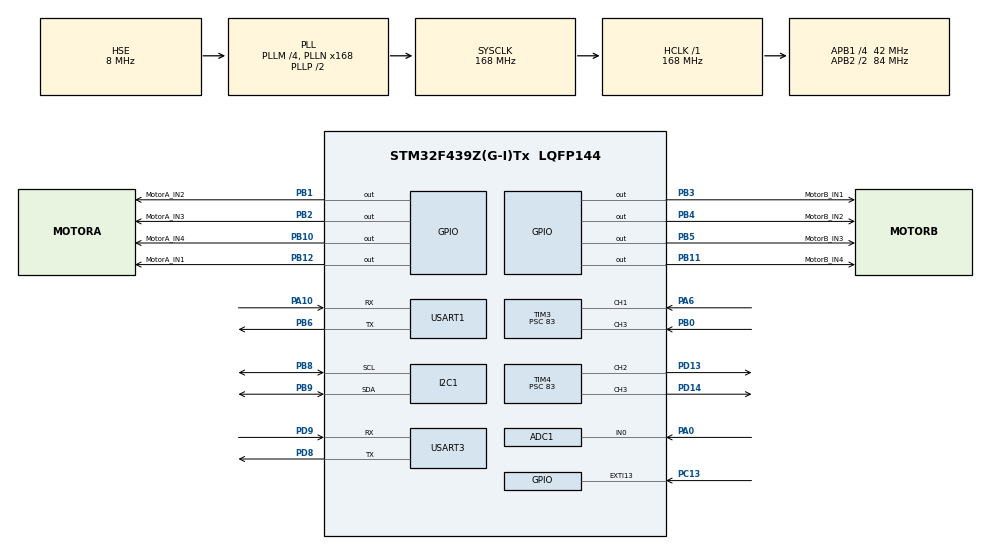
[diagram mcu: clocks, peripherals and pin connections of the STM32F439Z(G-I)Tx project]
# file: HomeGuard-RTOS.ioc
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ADC1.Channel-0\#ChannelRegularConversion=ADC_CHANNEL_0
ADC1.NbrOfConversionFlag=1
ADC1.Rank-0\#ChannelRegularConversion=1
ADC1.SamplingTime-0\#ChannelRegularConversion=ADC_SAMPLETIME_3CYCLES
ADC1.master=1
FREERTOS.Tasks01=defaultTask,24,128,StartDefaultTask,Default,NULL,Dynamic,NULL,NULL
FREERTOS.configENABLE_FPU=1
FREERTOS.configUSE_NEWLIB_REENTRANT=1
Mcu.Family=STM32F4
Mcu.Name=STM32F439Z(G-I)Tx
Mcu.Package=LQFP144
NVIC.EXTI15_10_IRQn=true\:5\:0\:false\:false\:true\:true\:true\:true\:true
NVIC.PriorityGroup=NVIC_PRIORITYGROUP_4
NVIC.TIM3_IRQn=true\:5\:0\:false\:false\:true\:true\:true\:true\:true
NVIC.TIM5_IRQn=true\:5\:0\:false\:false\:true\:true\:true\:true\:true
NVIC.TIM6_DAC_IRQn=true\:15\:0\:false\:false\:true\:false\:false\:true\:true
NVIC.TimeBase=TIM6_DAC_IRQn
NVIC.TimeBaseIP=TIM6
NVIC.USART1_IRQn=true\:5\:0\:false\:false\:true\:true\:true\:true\:true
PA0/WKUP.Signal=ADCx_IN0
PA10.Mode=Asynchronous
PA10.Signal=USART1_RX
PA6.Signal=S_TIM3_CH1
PB0.Signal=S_TIM3_CH3
PB1.GPIO_Label=MotorA_IN2
PB1.Signal=GPIO_Output
PB10.GPIO_Label=MotorA_IN4
PB10.Signal=GPIO_Output
PB11.GPIO_Label=MotorB_IN4
PB11.Signal=GPIO_Output
PB12.GPIO_Label=MotorA_IN1
PB12.Signal=GPIO_Output
PB2/BOOT1.GPIO_Label=MotorA_IN3
PB2/BOOT1.Signal=GPIO_Output
PB3.GPIO_Label=MotorB_IN1
PB3.Signal=GPIO_Output
PB4.GPIO_Label=MotorB_IN2
PB4.Signal=GPIO_Output
PB5.GPIO_Label=MotorB_IN3
PB5.Signal=GPIO_Output
PB6.Mode=Asynchronous
PB6.Signal=USART1_TX
PB8.Mode=I2C
PB8.Signal=I2C1_SCL
PB9.Mode=I2C
PB9.Signal=I2C1_SDA
PC13.GPIO_ModeDefaultEXTI=GPIO_MODE_IT_FALLING
PC13.Signal=GPXTI13
PC14/OSC32_IN.Mode=LSE-External-Oscillator
PC14/OSC32_IN.Signal=RCC_OSC32_IN
PC15/OSC32_OUT.Mode=LSE-External-Oscillator
PC15/OSC32_OUT.Signal=RCC_OSC32_OUT
PD13.Signal=S_TIM4_CH2
PD14.Signal=S_TIM4_CH3
PD8.Mode=Asynchronous
PD8.Signal=USART3_TX
PD9.Mode=Asynchronous
PD9.Signal=USART3_RX
PH0/OSC_IN.Mode=HSE-External-Oscillator
PH0/OSC_IN.Signal=RCC_OSC_IN
PH1/OSC_OUT.Mode=HSE-External-Oscillator
PH1/OSC_OUT.Signal=RCC_OSC_OUT
ProjectManager.HeapSize=0x200
ProjectManager.StackSize=0x400
ProjectManager.TargetToolchain=STM32CubeIDE
RCC.48MHZClocksFreq_Value=48000000
RCC.AHBFreq_Value=168000000
RCC.APB1CLKDivider=RCC_HCLK_DIV4
RCC.APB1Freq_Value=42000000
RCC.APB1TimFreq_Value=84000000
RCC.APB2CLKDivider=RCC_HCLK_DIV2
RCC.APB2Freq_Value=84000000
RCC.APB2TimCLKDivider=2
RCC.APB2TimFreq_Value=168000000
RCC.CortexFreq_Value=168000000
RCC.HCLKFreq_Value=168000000
RCC.HSE_VALUE=8000000
RCC.HSI_VALUE=16000000
RCC.PLLM=4
RCC.PLLMUL=RCC_PLL_MUL9
RCC.PLLN=168
RCC.PLLQ=7
RCC.PLLSourceVirtual=RCC_PLLSOURCE_HSE
RCC.PRESCALERUSB=RCC_USBCLKSOURCE_PLL_DIV1_5
RCC.SYSCLKFreq_VALUE=168000000
RCC.SYSCLKSource=RCC_SYSCLKSOURCE_PLLCLK
RCC.SYSCLKSourceVirtual=RCC_SYSCLKSOURCE_PLLCLK
RCC.USBFreq_Value=48000000
RCC.VCOOutputFreq_Value=336000000
RTC.Date=13
RTC.Month=RTC_MONTH_DECEMBER
RTC.WeekDay=RTC_WEEKDAY_SATURDAY
RTC.Year=25
SH.ADCx_IN0.0=ADC1_IN0,IN0
SH.S_TIM3_CH1.0=TIM3_CH1,Input_Capture1_from_TI1
SH.S_TIM3_CH3.0=TIM3_CH3,Input_Capture3_from_TI3
SH.S_TIM4_CH2.0=TIM4_CH2,PWM Generation2 CH2
SH.S_TIM4_CH3.0=TIM4_CH3,PWM Generation3 CH3
TIM3.Channel-Input_Capture1_from_TI1=TIM_CHANNEL_1
TIM3.Channel-Input_Capture3_from_TI3=TIM_CHANNEL_3
TIM3.Prescaler=83
TIM4.Channel-PWM\ Generation2\ CH2=TIM_CHANNEL_2
TIM4.Channel-PWM\ Generation3\ CH3=TIM_CHANNEL_3
TIM4.Period=49
TIM4.Prescaler=83
TIM4.Pulse-PWM\ Generation2\ CH2=10
TIM4.Pulse-PWM\ Generation3\ CH3=10
TIM5.Period=9
TIM5.Prescaler=8399
USART1.VirtualMode=VM_ASYNC
USART3.VirtualMode=VM_ASYNC
VP_FREERTOS_VS_CMSIS_V2.Mode=CMSIS_V2
VP_RTC_VS_RTC_Activate.Mode=RTC_Enabled
VP_RTC_VS_RTC_Calendar.Mode=RTC_Calendar
VP_SYS_VS_tim6.Mode=TIM6
VP_TIM4_VS_OPM.Mode=OPM_bit
VP_TIM5_VS_ClockSourceINT.Mode=Internal
board=NUCLEO-F439ZI

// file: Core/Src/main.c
/* USER CODE BEGIN Header */
/**
  ******************************************************************************
  * @file           : main.c
  * @brief          : Main program body
  ******************************************************************************
  * @attention
  *
  * Copyright (c) 2025 STMicroelectronics.
  * All rights reserved.
  *
  * This software is licensed under terms that can be found in the LICENSE file
  * in the root directory of this software component.
  * If no LICENSE file comes with this software, it is provided AS-IS.
  *
  ******************************************************************************
  */
/* USER CODE END Header */
#include "main.h"
#include "cmsis_os.h"
#include "adc.h"
#include "i2c.h"
#include "rtc.h"
#include "tim.h"
#include "usart.h"
#include "gpio.h"

/* USER CODE BEGIN Includes */
#include "system_manager.h"
#include <stdio.h>
/* USER CODE END Includes */

void SystemClock_Config(void);
void MX_FREERTOS_Init(void);

/* USER CODE BEGIN 0 */
int _write(int file, char* ptr, int size){
	HAL_UART_Transmit(&huart3, (uint8_t*)ptr, size, HAL_MAX_DELAY);
	return size;
}
/* USER CODE END 0 */

int main(void)
{

  /* MCU Configuration--------------------------------------------------------*/

  /* Reset of all peripherals, Initializes the Flash interface and the Systick. */
  HAL_Init();

  /* Configure the system clock */
  SystemClock_Config();

  /* Initialize all configured peripherals */
  MX_GPIO_Init();
  MX_ADC1_Init();
  MX_I2C1_Init();
  MX_RTC_Init();
  MX_USART1_UART_Init();
  MX_USART3_UART_Init();
  MX_TIM3_Init();
  MX_TIM4_Init();
  MX_TIM5_Init();
  /* USER CODE BEGIN 2 */
  System_Init();

  /* USER CODE END 2 */

  /* Init scheduler */
  osKernelInitialize();  /* Call init function for freertos objects (in cmsis_os2.c) */
  MX_FREERTOS_Init();

  /* Start scheduler */
  osThreadAttr_t systemTaskAttr = {
      .name = "SystemTask",
      .priority = osPriorityNormal,
      .stack_size = 1024
  };

  osThreadNew(System_Task, NULL, &systemTaskAttr);

  osKernelStart();

  /* We should never get here as control is now taken by the scheduler */
  /* Infinite loop */
  while (1)
  {

  }
}

void SystemClock_Config(void)
{
  RCC_OscInitTypeDef RCC_OscInitStruct = {0};
  RCC_ClkInitTypeDef RCC_ClkInitStruct = {0};

  /** Configure the main internal regulator output voltage
  */
  __HAL_RCC_PWR_CLK_ENABLE();
  __HAL_PWR_VOLTAGESCALING_CONFIG(PWR_REGULATOR_VOLTAGE_SCALE1);

  /** Initializes the RCC Oscillators according to the specified parameters
  * in the RCC_OscInitTypeDef structure.
  */
  RCC_OscInitStruct.OscillatorType = RCC_OSCILLATORTYPE_LSI|RCC_OSCILLATORTYPE_HSE;
  RCC_OscInitStruct.HSEState = RCC_HSE_ON;
  RCC_OscInitStruct.LSIState = RCC_LSI_ON;
  RCC_OscInitStruct.PLL.PLLState = RCC_PLL_ON;
  RCC_OscInitStruct.PLL.PLLSource = RCC_PLLSOURCE_HSE;
  RCC_OscInitStruct.PLL.PLLM = 4;
  RCC_OscInitStruct.PLL.PLLN = 168;
  RCC_OscInitStruct.PLL.PLLP = RCC_PLLP_DIV2;
  RCC_OscInitStruct.PLL.PLLQ = 7;
  if (HAL_RCC_OscConfig(&RCC_OscInitStruct) != HAL_OK)
  {
    Error_Handler();
  }

  /** Initializes the CPU, AHB and APB buses clocks
  */
  RCC_ClkInitStruct.ClockType = RCC_CLOCKTYPE_HCLK|RCC_CLOCKTYPE_SYSCLK
                              |RCC_CLOCKTYPE_PCLK1|RCC_CLOCKTYPE_PCLK2;
  RCC_ClkInitStruct.SYSCLKSource = RCC_SYSCLKSOURCE_PLLCLK;
  RCC_ClkInitStruct.AHBCLKDivider = RCC_SYSCLK_DIV1;
  RCC_ClkInitStruct.APB1CLKDivider = RCC_HCLK_DIV4;
  RCC_ClkInitStruct.APB2CLKDivider = RCC_HCLK_DIV2;

  if (HAL_RCC_ClockConfig(&RCC_ClkInitStruct, FLASH_LATENCY_5) != HAL_OK)
  {
    Error_Handler();
  }
}

void Error_Handler(void)
{
  __disable_irq();
  while (1)
  {
  }
}
